# PIC18F54Q71 register map
Vendor: Microchip
Registers are 8-bit, read-write, reset 0x0 unless marked. A register's access mark holds for its fields unless they carry their own. Addresses are absolute, and some are shared; only a register's first bit layout is shown; [hi:lo] are bit positions; {n}, {i} and the like mark numbered series.

## DOS_xxxxx_pps_mid_v2_output_8bit
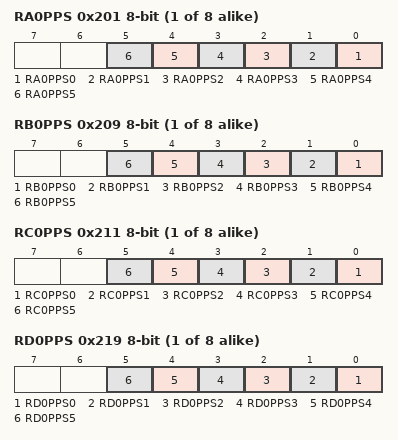
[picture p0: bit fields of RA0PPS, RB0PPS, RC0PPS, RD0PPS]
{0x201+i} RA{i}PPS (i=0..7)
  [n] RA{i}PPS{n} (n=0..5)
{0x209+i} RB{i}PPS (i=0..7)
  [n] RB{i}PPS{n} (n=0..5)
{0x211+i} RC{i}PPS (i=0..7)
  [n] RC{i}PPS{n} (n=0..5)
{0x219+i} RD{i}PPS (i=0..7)
  [n] RD{i}PPS{n} (n=0..5)
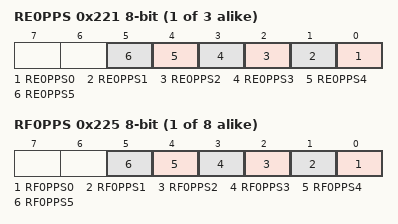
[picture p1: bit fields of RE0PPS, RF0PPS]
{0x221+i} RE{i}PPS (i=0..2)
  [n] RE{i}PPS{n} (n=0..5)
{0x225+i} RF{i}PPS (i=0..7)
  [n] RF{i}PPS{n} (n=0..5)

## DOS_xxxx_pps_mid
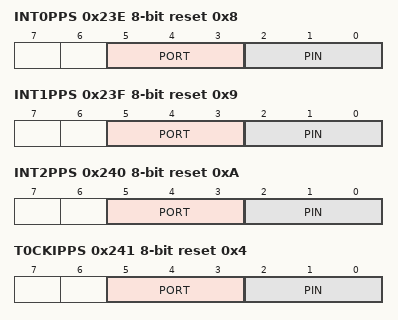
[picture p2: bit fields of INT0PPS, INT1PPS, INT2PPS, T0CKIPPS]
0x23E INT0PPS reset 0x8
  [5:3] PORT, [2:0] PIN
0x23F INT1PPS reset 0x9
  [5:3] PORT, [2:0] PIN
0x240 INT2PPS reset 0xA
  [5:3] PORT, [2:0] PIN
0x241 T0CKIPPS reset 0x4
  [5:3] PORT, [2:0] PIN
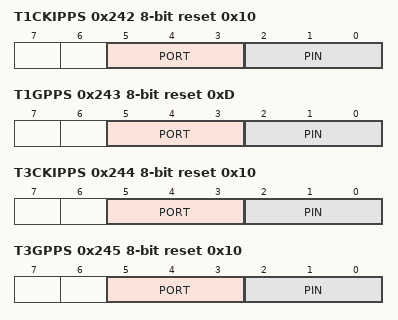
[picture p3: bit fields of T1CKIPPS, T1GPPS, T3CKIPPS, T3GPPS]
0x242 T1CKIPPS reset 0x10
  [5:3] PORT, [2:0] PIN
0x243 T1GPPS reset 0xD
  [5:3] PORT, [2:0] PIN
0x244 T3CKIPPS reset 0x10
  [5:3] PORT, [2:0] PIN
0x245 T3GPPS reset 0x10
  [5:3] PORT, [2:0] PIN
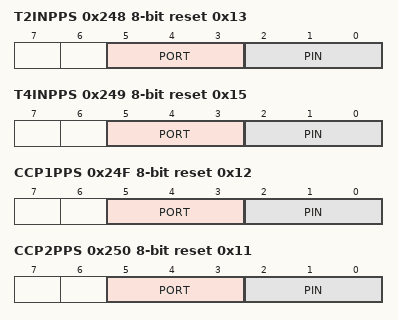
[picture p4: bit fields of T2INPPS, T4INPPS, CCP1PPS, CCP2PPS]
0x248 T2INPPS reset 0x13
  [5:3] PORT, [2:0] PIN
0x249 T4INPPS reset 0x15
  [5:3] PORT, [2:0] PIN
0x24F CCP1PPS reset 0x12
  [5:3] PORT, [2:0] PIN
0x250 CCP2PPS reset 0x11
  [5:3] PORT, [2:0] PIN
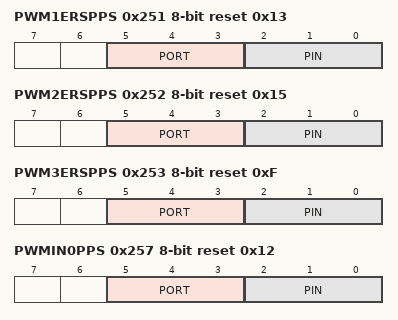
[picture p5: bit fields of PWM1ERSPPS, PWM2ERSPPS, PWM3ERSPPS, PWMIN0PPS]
0x251 PWM1ERSPPS reset 0x13
  [5:3] PORT, [2:0] PIN
0x252 PWM2ERSPPS reset 0x15
  [5:3] PORT, [2:0] PIN
0x253 PWM3ERSPPS reset 0xF
  [5:3] PORT, [2:0] PIN
0x257 PWMIN0PPS reset 0x12
  [5:3] PORT, [2:0] PIN
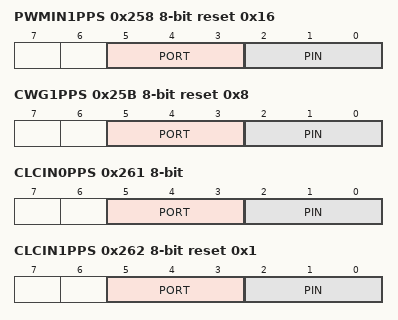
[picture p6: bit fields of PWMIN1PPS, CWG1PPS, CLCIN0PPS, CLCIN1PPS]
0x258 PWMIN1PPS reset 0x16
  [5:3] PORT, [2:0] PIN
0x25B CWG1PPS reset 0x8
  [5:3] PORT, [2:0] PIN
0x261 CLCIN0PPS
  [5:3] PORT, [2:0] PIN
0x262 CLCIN1PPS reset 0x1
  [5:3] PORT, [2:0] PIN
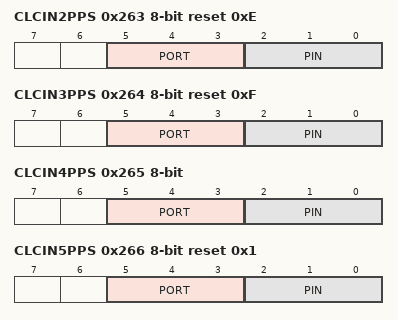
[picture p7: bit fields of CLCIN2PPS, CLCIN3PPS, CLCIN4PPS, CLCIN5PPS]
0x263 CLCIN2PPS reset 0xE
  [5:3] PORT, [2:0] PIN
0x264 CLCIN3PPS reset 0xF
  [5:3] PORT, [2:0] PIN
0x265 CLCIN4PPS
  [5:3] PORT, [2:0] PIN
0x266 CLCIN5PPS reset 0x1
  [5:3] PORT, [2:0] PIN
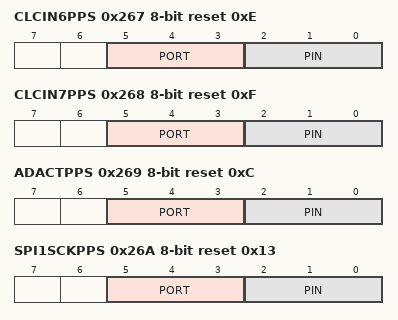
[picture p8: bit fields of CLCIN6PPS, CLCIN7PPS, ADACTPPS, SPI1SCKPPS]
0x267 CLCIN6PPS reset 0xE
  [5:3] PORT, [2:0] PIN
0x268 CLCIN7PPS reset 0xF
  [5:3] PORT, [2:0] PIN
0x269 ADACTPPS reset 0xC
  [5:3] PORT, [2:0] PIN
0x26A SPI1SCKPPS reset 0x13
  [5:3] PORT, [2:0] PIN
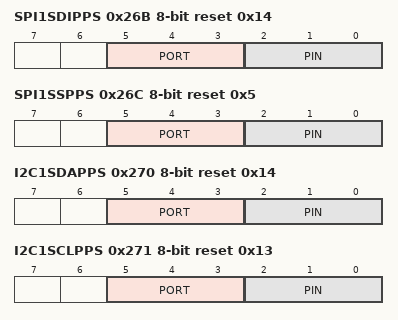
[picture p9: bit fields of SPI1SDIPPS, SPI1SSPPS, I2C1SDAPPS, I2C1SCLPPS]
0x26B SPI1SDIPPS reset 0x14
  [5:3] PORT, [2:0] PIN
0x26C SPI1SSPPS reset 0x5
  [5:3] PORT, [2:0] PIN
0x270 I2C1SDAPPS reset 0x14
  [5:3] PORT, [2:0] PIN
0x271 I2C1SCLPPS reset 0x13
  [5:3] PORT, [2:0] PIN
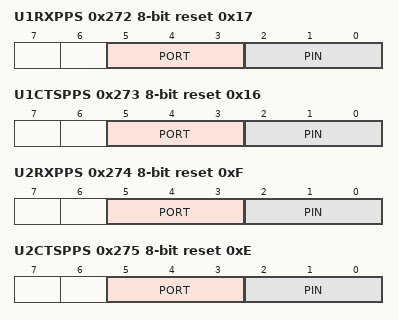
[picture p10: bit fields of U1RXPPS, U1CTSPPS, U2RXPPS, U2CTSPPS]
0x272 U1RXPPS reset 0x17
  [5:3] PORT, [2:0] PIN
0x273 U1CTSPPS reset 0x16
  [5:3] PORT, [2:0] PIN
0x274 U2RXPPS reset 0xF
  [5:3] PORT, [2:0] PIN
0x275 U2CTSPPS reset 0xE
  [5:3] PORT, [2:0] PIN
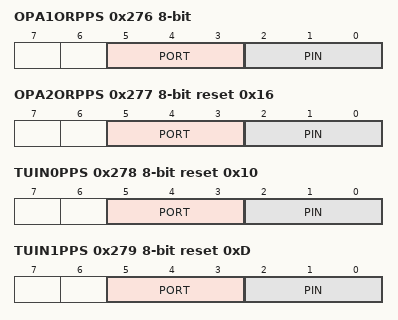
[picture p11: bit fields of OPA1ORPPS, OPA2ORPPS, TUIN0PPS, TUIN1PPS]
0x276 OPA1ORPPS
  [5:3] PORT, [2:0] PIN
0x277 OPA2ORPPS reset 0x16
  [5:3] PORT, [2:0] PIN
0x278 TUIN0PPS reset 0x10
  [5:3] PORT, [2:0] PIN
0x279 TUIN1PPS reset 0xD
  [5:3] PORT, [2:0] PIN
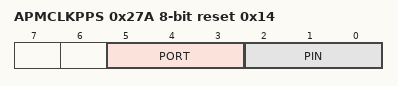
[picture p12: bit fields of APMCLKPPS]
0x27A APMCLKPPS reset 0x14
  [5:3] PORT, [2:0] PIN

## pad
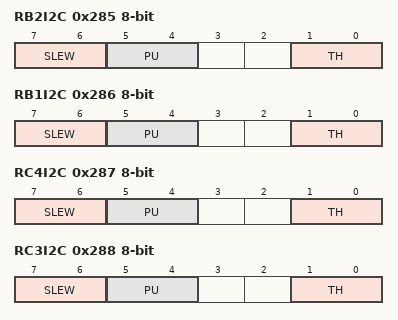
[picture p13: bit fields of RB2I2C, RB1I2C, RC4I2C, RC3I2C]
0x285 RB2I2C
  [7:6] SLEW, [5:4] PU, [1:0] TH
0x286 RB1I2C
  [7:6] SLEW, [5:4] PU, [1:0] TH
0x287 RC4I2C
  [7:6] SLEW, [5:4] PU, [1:0] TH
0x288 RC3I2C
  [7:6] SLEW, [5:4] PU, [1:0] TH

## i2c
0x289 I2C1RXB ro reset not defined — I2C RECEIVE BUFFER REGISTER (power-on value xxxxxxxx)
  [7:0] RXB
0x28A I2C1TXB wo reset not defined — I2C TRANSMIT BUFFER REGISTER (power-on value xxxxxxxx)
  [7:0] TXB
0x28B I2C1CNTL reset not defined — (power-on value xxxxxxxx)
  [7:0] CNT
0x28C I2C1CNTH reset not defined — (power-on value xxxxxxxx)
  [7:0] CNT
0x28D I2C1ADB0 reset not defined — I2C ADDRESS BUFFER REGISTER 0 (power-on value xxxxxxxx)
  [7:0] ADB
0x28E I2C1ADB1 reset not defined — I2C ADDRESS BUFFER REGISTER 1 (power-on value xxxxxxxx)
  [7:0] ADB
0x28F I2C1ADR0 reset 0xFF — I2C ADDRESS REGISTER 0
  [7:0] ADR
0x290 I2C1ADR1 reset 0xFE — I2C ADDRESS REGISTER 1
  [7:1] ADR
0x291 I2C1ADR2 reset 0xFF — I2C ADDRESS REGISTER 2
  [7:0] ADR
0x292 I2C1ADR3 reset 0xFE — I2C ADDRESS REGISTER 3
  [7:1] ADR
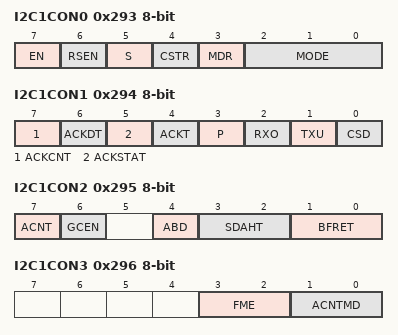
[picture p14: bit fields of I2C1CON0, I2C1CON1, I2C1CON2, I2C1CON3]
0x293 I2C1CON0 — I2C CONTROL REGISTER 0
  [7] EN
  [6] RSEN
  [5] S — (can only be set)
  [4] CSTR — (can only be cleared)
  [3] MDR ro
  [2:0] MODE
0x294 I2C1CON1 — I2C CONTROL REGISTER 1
  [7] ACKCNT
  [6] ACKDT
  [5] ACKSTAT ro
  [4] ACKT ro
  [3] P — (can only be set)
  [2] RXO
  [1] TXU
  [0] CSD
0x295 I2C1CON2 — I2C CONTROL REGISTER 2
  [7] ACNT, [6] GCEN, [4] ABD, [3:2] SDAHT, [1:0] BFRET
0x296 I2C1CON3 — I2C CONTROL REGISTER 3
  [3:2] FME, [1:0] ACNTMD
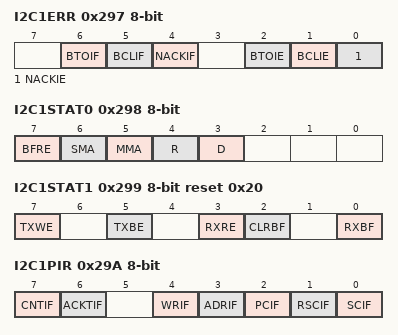
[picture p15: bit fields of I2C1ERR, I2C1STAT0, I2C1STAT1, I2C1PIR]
0x297 I2C1ERR — I2C ERROR REGISTER
  [6] BTOIF, [5] BCLIF, [4] NACKIF, [2] BTOIE, [1] BCLIE, [0] NACKIE
0x298 I2C1STAT0 ro — I2C STATUS REGISTER 0
  [7] BFRE
  [6] SMA
  [5] MMA
  [4] R — Read/Write Information bit
  [3] D — Data/Address bit
0x299 I2C1STAT1 reset 0x20 — I2C STATUS REGISTER 1
  [7] TXWE
  [5] TXBE ro
  [3] RXRE
  [2] CLRBF — (can only be set)
  [0] RXBF ro
0x29A I2C1PIR — I2C PERIPHERAL INTERRUPT FLAG REGISTER
  [7] CNTIF, [6] ACKTIF, [4] WRIF, [3] ADRIF, [2] PCIF, [1] RSCIF, [0] SCIF
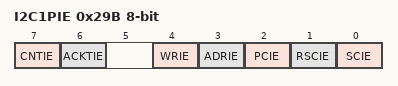
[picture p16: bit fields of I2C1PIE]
0x29B I2C1PIE — I2C PERIPHERAL INTERRUPT ENABLE REGISTER
  [7] CNTIE, [6] ACKTIE, [4] WRIE, [3] ADRIE, [2] PCIE, [1] RSCIE, [0] SCIE
0x29C I2C1BTO reset not defined — I2C BUS TIME OUT SELECTION REGISTER (power-on value xxxxxxxx)
  [7] TOREC, [6] TOBY32, [5:0] TOTIME
0x29D I2C1BAUD reset not defined — I2C BAUD RATE PRESCALER REGISTER (power-on value xxxxxxxx)
  [7:0] BAUD
0x29E I2C1CLK — I2C CLOCK SELECTION REGISTER
  [4:0] CLK
0x29F I2C1BTOC reset not defined — (power-on value ----xxxx)
  [3:0] BTOC
